VERSION ""

NS_ :

BS_:

BU_: SUT Tester

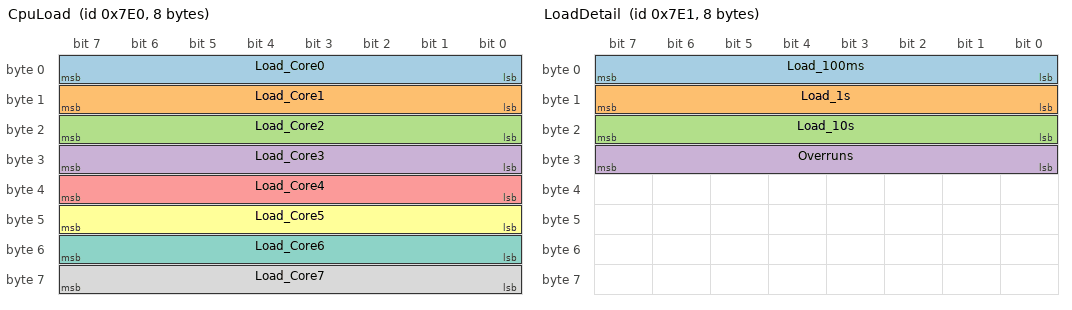
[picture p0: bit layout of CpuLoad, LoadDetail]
BO_ 2016 CpuLoad: 8 SUT
 SG_ Load_Core0 : 0|8@1+ (1,0) [0|100] "%" Tester
 SG_ Load_Core1 : 8|8@1+ (1,0) [0|100] "%" Tester
 SG_ Load_Core2 : 16|8@1+ (1,0) [0|100] "%" Tester
 SG_ Load_Core3 : 24|8@1+ (1,0) [0|100] "%" Tester
 SG_ Load_Core4 : 32|8@1+ (1,0) [0|100] "%" Tester
 SG_ Load_Core5 : 40|8@1+ (1,0) [0|100] "%" Tester
 SG_ Load_Core6 : 48|8@1+ (1,0) [0|100] "%" Tester
 SG_ Load_Core7 : 56|8@1+ (1,0) [0|100] "%" Tester

BO_ 2017 LoadDetail: 8 SUT
 SG_ Load_100ms : 0|8@1+ (1,0) [0|100] "%" Tester
 SG_ Load_1s : 8|8@1+ (1,0) [0|100] "%" Tester
 SG_ Load_10s : 16|8@1+ (1,0) [0|100] "%" Tester
 SG_ Overruns : 24|8@1+ (1,0) [0|255] "" Tester

BO_ 291 CmdFrame: 4 Tester
 SG_ Command : 0|32@1+ (1,0) [0|4294967295] "" SUT

BO_ 512 WorkloadFrame: 4 SUT
 SG_ Workload : 0|32@1+ (1,0) [0|4294967295] "" Tester

BO_ 513 M4LoadFrame: 8 SUT
 SG_ M4Count : 0|32@1+ (1,0) [0|4294967295] "" Tester
 SG_ M4Acc : 32|32@1+ (1,0) [0|4294967295] "" Tester

BA_DEF_ BO_ "GenMsgCycleTime" INT 0 100000;
BA_DEF_DEF_ "GenMsgCycleTime" 0;
BA_ "GenMsgCycleTime" BO_ 2016 500;
BA_ "GenMsgCycleTime" BO_ 2017 500;
